# A31G34x register map
Vendor: VENDOR ABOV Semiconductor Co., Ltd.; Series: A31G34x; File version: 1.0
CPU: CM0+ r0p1, little endian, no MPU, no FPU, VTOR, 2 interrupt priority bits
Registers are 32-bit, read-only, no defined reset value unless marked. A register's access mark holds for its fields unless they carry their own. Offsets are from the block's base; [hi:lo] are bit positions; {n}, {i} and the like mark numbered series; 'fields as' and 'values as' point back to an identical list.

## USART10 — USART 10 (UART + SPI)
Base 0x40003800
Same registers: USART11 0x40003900, USART12 0x40003A00, USART13 0x40003B00
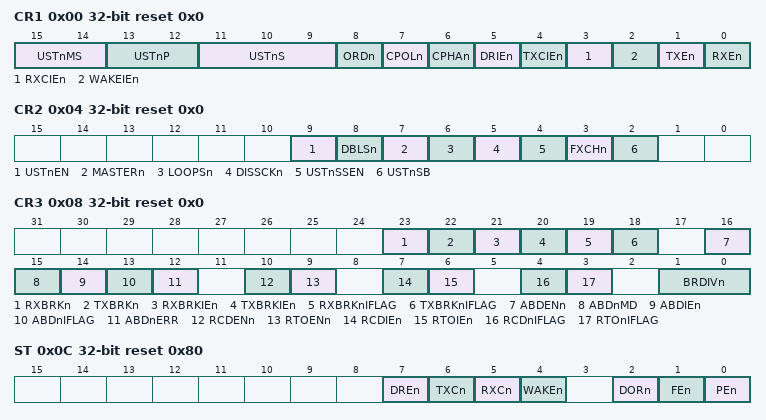
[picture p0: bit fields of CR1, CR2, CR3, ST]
0x00 CR1 rw reset 0x0 — USART1n Control Register 1
  [15:14] USTnMS — USART1n Operation Mode Selection
    0=Asynchronous Mode (UART); 1=Synchronous Mode (USRT); 2=LIN (Local Interconnection Network (LIN)); 3=SPI (SPI Mode)
  [13:12] USTnP — Selects Parity Generation and Check method (only UART mode)
    0=No (No Parity); 2=Even Parity; 3=Odd (Odd Parity)
  [11:9] USTnS — Selects the length of data bit in a frame when Asynchronous or Synchronous mode
    {v}={v+5}bit (v=0..3); 7=9bit
  [8] ORDn — Selects the first data bit to be transmitted (only SPI mode)
    0=lsbFirst; 1=msbFirst
  [7] CPOLn — Selects the Clock Polarity of ACK in Synchronous or SPI mode
    0=IdleLow (SCK to 0 when idle); 1=IdleHigh (SCK to 1 when idle)
  [6] CPHAn — The CPOLn and this bit determine if data are sampled on the leading or trailing edge of SCK (only SPI mode)
    0=StartIdle (Start with idle state.); 1=StartInverted (Start with inverted idle state.)
  [5] DRIEn — Transmit Data Register Empty Interrupt Enable
    0=Disable the transmit data empty interrupt; 1=Enable the transmit data empty interrupt
  [4] TXCIEn — Transmit Complete Interrupt Enable
    0=Disable transmit complete interrupt; 1=Enable transmit complete interrupt
  [3] RXCIEn — Receive Complete Interrupt Enable
    0=Disable receive complete interrupt; 1=Enable receive complete interrupt
  [2] WAKEIEn — Asynchronous Wake-Up Interrupt Enable in Deep Sleep Mode (only UART mode)
    0=Disable asynchronous wake-up interrupt; 1=Enable asynchronous wake-up interrupt. (Only used for wake-up)
  [1] TXEn — Enable the transmitter unit.
    0=Disable (Transmitter is disabled.); 1=Enable (Transmitter is enabled.)
  [0] RXEn — Enable the receiver unit.
    0=Disable (Receiver is disabled.); 1=Enable (Receiver is enabled.)
0x04 CR2 rw reset 0x0 — USART1n Control Register 2
  [9] USTnEN — Activate USART1n Block by supplying
    0=Disable USARTn block; 1=Enable USARTn block
  [8] DBLSn — Selects receiver sampling rate (only UART and LIN mode)
    0=Normal speed operation; 1=Double speed operation
  [7] MASTERn — Selects master or slave in SPI or Synchronous mode and controls the direction of SCK pin
    0=Slave operation (External clock for SCK); 1=Master operation (Internal clock for SCK)
  [6] LOOPSn — 1-wire Half-Duplex Communication on Asynchronous Mode or Loop Back for Test on SPI and Asynchronous Mode
    0=Disable (Normal operation); 1=Enable (1-wire half-duplex communication (UART); Loop back(USRT/SPI))
  [5] DISSCKn — In synchronous mode operation, selects the waveform of SCK output
    0=Always (SCK is free-running while USART is enabled in synchronous master mode.); 1=FrameOnly (SCK is active while any frame is on transferring.)
  [4] USTnSSEN — This bit controls the SS pin operation (only SPI mode)
    0=Disable SS; 1=Enable SS. (The SS pin should be configured as an alternative function)
  [3] FXCHn — SPI port function exchange control bit (only SPI mode)
    0=NoEffect; 1=Exchange MOSI and MISO function
  [2] USTnSB — Selects the length of stop bit in Asynchronous or Synchronous mode
    0=1bit (1 Stop bit); 1=2bit (2 Stop bit)
0x08 CR3 rw reset 0x0 — USART1n Control Register 3
  [23] RXBRKn — Rx Break Field Length (Only LIN mode)
    0=Min10Bits (10 '0' bits or more); 1=Min11Bits (11 '0' bits or more)
  [22] TXBRKn — Tx Break Field (Only LIN mode)
    0=NoEffect; 1=Enable (Transmit Tx break (13 '0' bits + 2 '1' bits, 000000000000011b, automatically cleared))
  [21] RXBRKIEn — Rx Break Field Detection Interrupt Enable bit (Only LIN mode)
    0=Disable Rx break detection interrupt; 1=Enable Rx break detection interrupt
  [20] TXBRKIEn — Tx Break Field Completion Interrupt Enable bit (Only LIN mode)
    0=Disable Tx break completion interrupt; 1=Enable Tx break completion interrupt
  [19] RXBRKnIFLAG — Rx Break Field Detection Interrupt flag. This bit is set when LIN break is detected.
    0=No request occurred; 1=Request occurred, This bit is cleared to '0' when write '1'
  [18] TXBRKnIFLAG — Tx Break Field Completion Interrupt flag. This bit is set when Tx break field is completely transmitted.
    values as RXBRKnIFLAG
  [16] ABDENn — Auto Baud Rate Detection Enable bit.
    0=Disable auto baud rate detection; 1=Enable auto baud rate detection. (This bit is automatically cleared after operation)
  [15] ABDnMD — Auto Baud Rate Detection Mode
    0=Mode 0, The start bit is used to measure the baud rate (The 1st bit must be '1b'); 1=Mode 1, The 0x55 character is used to measure the baud rate detection
  [14] ABDIEn — Auto Baud Rate Detection Interrupt Enable
    0=Disable auto baud rate detection interrupt; 1=Enable auto baud rate detection interrupt
  [13] ABDnIFLAG — Auto Baud Rate Detection Interrupt Flag. This bit is set to '1b' when the auto baud rate detection finishes, whether an error occurs or not.
    values as RXBRKnIFLAG
  [12] ABDnERR — Auto Baud Rate Detection Error bit. This bit is set to '1b' if the clock counting values are not between 16 and 65536 on the normal speed operation (DBLSn = 0) or between 8 and 32768 on the double speed operation (DBLSn = 1).
    0=No error occurs; 1=Error (An error occurs, This bit is cleared to '0' when write '1'.)
  [10] RCDENn — Receive Character Detection Function Enable
    0=Disable receive detection function; 1=Enable receive detection function
  [9] RTOENn — Receive Time Out Function Enable
    0=Disable receive time out function; 1=Enable receive time out function
  [7] RCDIEn — Receive Character Detection Interrupt Enable
    0=Disable receive character detection interrupt; 1=Enable receive character detection interrupt
  [6] RTOIEn — Receive Time Out Interrupt Enable
    0=Disable receive time out interrupt; 1=Enable receive time out interrupt
  [4] RCDnIFLAG — Receive Character detection Interrupt Flag
    values as RXBRKnIFLAG
  [3] RTOnIFLAG — Receive Time Out Interrupt Flag
    values as RXBRKnIFLAG
  [1:0] BRDIVn — Baud Rate Clock Dividing Selection for Receive Time Out bits (only asynchronous and LIN mode).
    0=fBR1; 1=fBR8; 2=fBR64; 3=fBR512
0x0C ST rw reset 0x80 — USART1n Status Register
  [7] DREn — Transmit Data Register Empty Interrupt Flag
    0=NotEmpty (Not transferred to the transmit shift register.); 1=Empty (Transferred to the transmit shift register.)
  [6] TXCn — Transmit Complete Interrupt Flag
    0=No request occurred; 1=TxComplete (The data in the transmit shift register are shifted out completely. This bit is cleared to '0' when write '1'.)
  [5] RXCn — Receive Complete Interrupt Flag
    0=No request occurred; 1=RxComplete (There is data in the receive data register. This bit is cleared to '0' when write '1'.)
  [4] WAKEn — Asynchronous Wake-Up Interrupt Flag
    values as CR3.RXBRKnIFLAG
  [2] DORn — Data Overrun
    0=NotDetected (No data overrun); 1=Detected (Data overrun detected, This bit is cleared to '0' when write '1'.)
  [1] FEn — Frame Error
    0=NotDetected (No frame error); 1=Detected (Frame error detected, This bit is cleared to '0' when write '1'.)
  [0] PEn — Parity Error
    0=NotDetected (No parity error); 1=Detected (Parity error detected, This bit is cleared to '0' when write '1'.)
0x10 BDR rw reset 0xFFF — USART1n Baud Rate Generation Register
  [11:0] BDATA — The value in this register is used to generate internal baud rate in UART mode or to generate SCK clock in SPI mode
0x14 RDR reset 0x0 — USART1n Receive Data Register
  [8:0] RDATA — Receive Data
0x18 TDR rw reset 0x0 — USART1n Transmit Data Register
  [8:0] TDATA — Transmit Data
0x1C RTODR rw reset 0xFF — USART1n Receive Time Out Data Register
  [7:0] RTOD — USART1n Receive Time Out Data
0x20 RCDR rw reset 0x0 — USART1n Receive Character Detection Data Register
  [7:0] RCDD — USART1n Receive Character Detection Data
